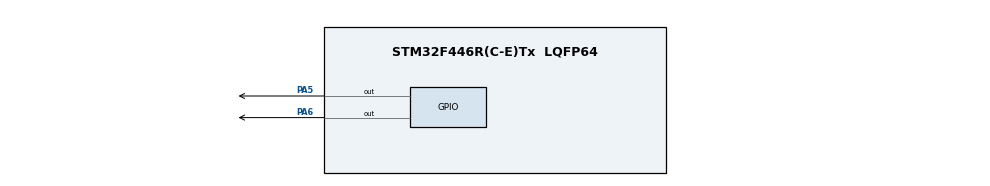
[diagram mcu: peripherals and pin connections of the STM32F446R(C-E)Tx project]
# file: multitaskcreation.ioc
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Mcu.Family=STM32F4
Mcu.Name=STM32F446R(C-E)Tx
Mcu.Package=LQFP64
NVIC.PriorityGroup=NVIC_PRIORITYGROUP_4
NVIC.TIM1_UP_TIM10_IRQn=true\:15\:0\:false\:false\:true\:false\:true\:true
NVIC.TimeBase=TIM1_UP_TIM10_IRQn
NVIC.TimeBaseIP=TIM1
PA13.Mode=Serial_Wire
PA13.Signal=SYS_JTMS-SWDIO
PA14.Mode=Serial_Wire
PA14.Signal=SYS_JTCK-SWCLK
PA5.Signal=GPIO_Output
PA6.Signal=GPIO_Output
ProjectManager.HeapSize=0x200
ProjectManager.StackSize=0x400
ProjectManager.TargetToolchain=STM32CubeIDE
RCC.CortexFreq_Value=16000000
RCC.USBFreq_Value=96000000
RCC.VCOOutputFreq_Value=192000000
VP_SYS_VS_tim1.Mode=TIM1
board=custom

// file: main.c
/* USER CODE BEGIN Header */
/**
  ******************************************************************************
  * @file           : main.c
  * @brief          : Main program body
  ******************************************************************************
  * @attention
  *
  * Copyright (c) 2025 STMicroelectronics.
  * All rights reserved.
  *
  * This software is licensed under terms that can be found in the LICENSE file
  * in the root directory of this software component.
  * If no LICENSE file comes with this software, it is provided AS-IS.
  *
  ******************************************************************************
  */
/* USER CODE END Header */
#include "main.h"

/* USER CODE BEGIN Includes */
#include "FreeRTOS.h"
#include "task.h"
/* USER CODE END Includes */

/* USER CODE BEGIN PV */
TaskHandle_t xGreenLedTask1Handle;
TaskHandle_t xGreenLedTask2Handle;
/* USER CODE END PV */

void SystemClock_Config(void);
static void MX_GPIO_Init(void);
/* USER CODE BEGIN PFP */
void vGreenLedTask1(void *pvParameters);
void vGreenLedTask2(void *pvParameters);
/* USER CODE END PFP */

int main(void)
{

  /* MCU Configuration--------------------------------------------------------*/

  /* Reset of all peripherals, Initializes the Flash interface and the Systick. */
  HAL_Init();

  /* Configure the system clock */
  SystemClock_Config();

  /* Initialize all configured peripherals */
  MX_GPIO_Init();
  /* USER CODE BEGIN 2 */
  xTaskCreate(vGreenLedTask1,"Green Led Task1",128,NULL,1,&xGreenLedTask1Handle);
  xTaskCreate(vGreenLedTask2,"Green Led Task2",128,NULL,1,&xGreenLedTask2Handle);
  vTaskStartScheduler();
  /* USER CODE END 2 */

  /* Infinite loop */
  while (1)
  {

  }
}

void SystemClock_Config(void)
{
  RCC_OscInitTypeDef RCC_OscInitStruct = {0};
  RCC_ClkInitTypeDef RCC_ClkInitStruct = {0};

  /** Configure the main internal regulator output voltage
  */
  __HAL_RCC_PWR_CLK_ENABLE();
  __HAL_PWR_VOLTAGESCALING_CONFIG(PWR_REGULATOR_VOLTAGE_SCALE3);

  /** Initializes the RCC Oscillators according to the specified parameters
  * in the RCC_OscInitTypeDef structure.
  */
  RCC_OscInitStruct.OscillatorType = RCC_OSCILLATORTYPE_HSI;
  RCC_OscInitStruct.HSIState = RCC_HSI_ON;
  RCC_OscInitStruct.HSICalibrationValue = RCC_HSICALIBRATION_DEFAULT;
  RCC_OscInitStruct.PLL.PLLState = RCC_PLL_NONE;
  if (HAL_RCC_OscConfig(&RCC_OscInitStruct) != HAL_OK)
  {
    Error_Handler();
  }

  /** Initializes the CPU, AHB and APB buses clocks
  */
  RCC_ClkInitStruct.ClockType = RCC_CLOCKTYPE_HCLK|RCC_CLOCKTYPE_SYSCLK
                              |RCC_CLOCKTYPE_PCLK1|RCC_CLOCKTYPE_PCLK2;
  RCC_ClkInitStruct.SYSCLKSource = RCC_SYSCLKSOURCE_HSI;
  RCC_ClkInitStruct.AHBCLKDivider = RCC_SYSCLK_DIV1;
  RCC_ClkInitStruct.APB1CLKDivider = RCC_HCLK_DIV1;
  RCC_ClkInitStruct.APB2CLKDivider = RCC_HCLK_DIV1;

  if (HAL_RCC_ClockConfig(&RCC_ClkInitStruct, FLASH_LATENCY_0) != HAL_OK)
  {
    Error_Handler();
  }
}

static void MX_GPIO_Init(void)
{
  GPIO_InitTypeDef GPIO_InitStruct = {0};

  /* GPIO Ports Clock Enable */
  __HAL_RCC_GPIOA_CLK_ENABLE();

  /*Configure GPIO pin Output Level */
  HAL_GPIO_WritePin(GPIOA, GPIO_PIN_5|GPIO_PIN_6, GPIO_PIN_RESET);

  /*Configure GPIO pins : PA5 PA6 */
  GPIO_InitStruct.Pin = GPIO_PIN_5|GPIO_PIN_6;
  GPIO_InitStruct.Mode = GPIO_MODE_OUTPUT_PP;
  GPIO_InitStruct.Pull = GPIO_NOPULL;
  GPIO_InitStruct.Speed = GPIO_SPEED_FREQ_LOW;
  HAL_GPIO_Init(GPIOA, &GPIO_InitStruct);

}

/* USER CODE BEGIN 4 */
void vGreenLedTask1(void *pvParameters)
{
	for(;;)
	HAL_GPIO_TogglePin(GPIOA, GPIO_PIN_5);
	vTaskDelay(pdMS_TO_TICKS(1000));
}
void vGreenLedTask2(void *pvParameters)
{
	for(;;)
	HAL_GPIO_TogglePin(GPIOA, GPIO_PIN_6);
	vTaskDelay(pdMS_TO_TICKS(2000));
}
/* USER CODE END 4 */

void HAL_TIM_PeriodElapsedCallback(TIM_HandleTypeDef *htim)
{
  if (htim->Instance == TIM1) {
    HAL_IncTick();
  }
}

void Error_Handler(void)
{
  __disable_irq();
  while (1)
  {
  }
}
